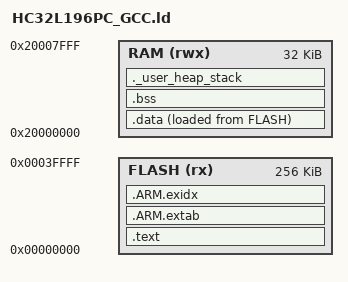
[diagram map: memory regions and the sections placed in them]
/* Highest address of the user mode stack */
_estack = ORIGIN(RAM) + LENGTH(RAM); /* end of "RAM" Ram type memory */

_Min_Heap_Size = 0x1000; /* required amount of heap  */
_Min_Stack_Size = 0x1000; /* required amount of stack */

/* Linker script to configure memory regions. */
MEMORY
{
  FLASH (rx)  : ORIGIN = 0x00000000, LENGTH = 256K
  RAM   (rwx) : ORIGIN = 0x20000000, LENGTH = 32K
}


/* Linker script to place sections and symbol values. Should be used together
 * with other linker script that defines memory regions FLASH and RAM.
 * It references following symbols, which must be defined in code:
 *   Reset_Handler : Entry of reset handler
 *
 * It defines following symbols, which code can use without definition:
 *   __exidx_start
 *   __exidx_end
 *   __copy_table_start__
 *   __copy_table_end__
 *   __zero_table_start__
 *   __zero_table_end__
 *   __etext
 *   __data_start__
 *   __preinit_array_start
 *   __preinit_array_end
 *   __init_array_start
 *   __init_array_end
 *   __fini_array_start
 *   __fini_array_end
 *   __data_end__
 *   __bss_start__
 *   __bss_end__
 *   __end__
 *   end
 *   __HeapLimit
 *   __StackLimit
 *   __StackTop
 *   __stack
 */
ENTRY(Reset_Handler)

SECTIONS
{
	.text :
	{
		KEEP(*(.vectors))
		*(.text*)

		KEEP(*(.init))
		KEEP(*(.fini))

		/* .ctors */
		*crtbegin.o(.ctors)
		*crtbegin?.o(.ctors)
		*(EXCLUDE_FILE(*crtend?.o *crtend.o) .ctors)
		*(SORT(.ctors.*))
		*(.ctors)

		/* .dtors */
 		*crtbegin.o(.dtors)
 		*crtbegin?.o(.dtors)
 		*(EXCLUDE_FILE(*crtend?.o *crtend.o) .dtors)
 		*(SORT(.dtors.*))
 		*(.dtors)

		*(.rodata*)

		KEEP(*(.eh_frame*))
	} > FLASH

	.ARM.extab :
	{
		*(.ARM.extab* .gnu.linkonce.armextab.*)
	} > FLASH

	__exidx_start = .;
	.ARM.exidx :
	{
		*(.ARM.exidx* .gnu.linkonce.armexidx.*)
	} > FLASH
	__exidx_end = .;

	/* To copy multiple ROM to RAM sections,
	 * uncomment .copy.table section and,
	 * define __STARTUP_COPY_MULTIPLE in startup_ARMCMx.S */
	/*
	.copy.table :
	{
		. = ALIGN(4);
		__copy_table_start__ = .;
		LONG (__etext)
		LONG (__data_start__)
		LONG (__data_end__ - __data_start__)
		LONG (__etext2)
		LONG (__data2_start__)
		LONG (__data2_end__ - __data2_start__)
		__copy_table_end__ = .;
	} > FLASH
	*/

	/* To clear multiple BSS sections,
	 * uncomment .zero.table section and,
	 * define __STARTUP_CLEAR_BSS_MULTIPLE in startup_ARMCMx.S */
	/*
	.zero.table :
	{
		. = ALIGN(4);
		__zero_table_start__ = .;
		LONG (__bss_start__)
		LONG (__bss_end__ - __bss_start__)
		LONG (__bss2_start__)
		LONG (__bss2_end__ - __bss2_start__)
		__zero_table_end__ = .;
	} > FLASH
	*/

	/* Used by the startup to initialize data */
	_sidata = LOADADDR(.data);

	/* Initialized data sections into "RAM" Ram type memory */
	.data :
	{
		. = ALIGN(4);
		_sdata = .;
		__data_start__ = .;
		*(vtable)
		*(.data*)

		. = ALIGN(4);
		/* preinit data */
		PROVIDE_HIDDEN (__preinit_array_start = .);
		KEEP(*(.preinit_array))
		PROVIDE_HIDDEN (__preinit_array_end = .);

		. = ALIGN(4);
		/* init data */
		PROVIDE_HIDDEN (__init_array_start = .);
		KEEP(*(SORT(.init_array.*)))
		KEEP(*(.init_array))
		PROVIDE_HIDDEN (__init_array_end = .);


		. = ALIGN(4);
		/* finit data */
		PROVIDE_HIDDEN (__fini_array_start = .);
		KEEP(*(SORT(.fini_array.*)))
		KEEP(*(.fini_array))
		PROVIDE_HIDDEN (__fini_array_end = .);

		KEEP(*(.jcr*))
		. = ALIGN(4);
		/* All data end */
		_edata = .;
		__data_end__ = .;

	} > RAM AT> FLASH

	/* Uninitialized data section */
	. = ALIGN(4);
	.bss :
	{
		/* This is used by the startup in order to initialize the .bss secion */
		_sbss = .;         /* define a global symbol at bss start */
		__bss_start__ = _sbss;
		*(.bss)
		*(.bss*)
		*(COMMON)

		. = ALIGN(4);
		_ebss = .;         /* define a global symbol at bss end */
		__bss_end__ = _ebss;
	} >RAM

	/* User_heap_stack section, used to check that there is enough "RAM" Ram  type memory left */
	._user_heap_stack :
	{
		. = ALIGN(8);
		PROVIDE ( end = . );
		PROVIDE ( _end = . );
		. = . + _Min_Heap_Size;
		. = . + _Min_Stack_Size;
		. = ALIGN(8);
	} >RAM
}
